# AES register map
Vendor: Texas Instruments
Registers are 32-bit, write-only, no defined reset value unless marked. A register's access mark holds for its fields unless they carry their own. Offsets are as the file gives them; [hi:lo] are bit positions; {n}, {i} and the like mark numbered series; 'fields as' and 'values as' point back to an identical list.

## AES (part 2 of 2) — Register fields should be considered static unless otherwise noted as dynamic.
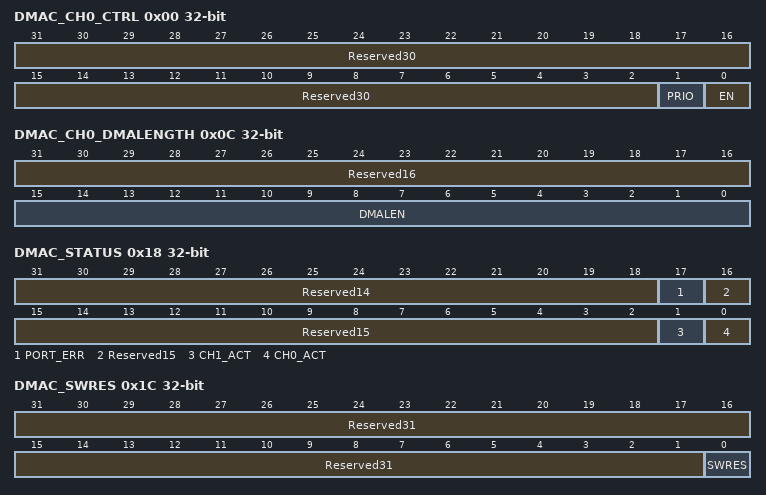
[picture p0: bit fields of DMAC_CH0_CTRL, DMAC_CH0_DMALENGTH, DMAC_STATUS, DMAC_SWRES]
0x00 DMAC_CH0_CTRL rw — Channel control This register is used for channel enabling and priority selection. When a channel is disabled, it becomes inactive only when all ongoing requests are finished.
  [31:2] Reserved30 — Should be written with 0s and ignored on read
  [1] PRIO — Channel priority 0: Low 1: High If both channels have the same priority, access of the channels to the external port is arbitrated using the round robin scheme. If one channel has a high priority and another one low, the channel with the high priority is served first, in case of simultaneous access requests.
  [0] EN — Channel enable 0: Disabled 1: Enable Note: Disabling an active channel interrupts the DMA operation. The ongoing block transfer completes, but no new transfers are requested.
0x04 DMAC_CH0_EXTADDR rw — Channel external address
  [31:0] ADDR — Channel external address value When read during operation, it holds the last updated external address after being sent to the master interface.
0x0C DMAC_CH0_DMALENGTH rw — Channel DMA length
  [31:16] Reserved16 — Should be written with 0s and ignored on read
  [15:0] DMALEN — Channel DMA length in bytes During configuration, this register contains the DMA transfer length in bytes. During operation, it contains the last updated value of the DMA transfer length after being sent to the master interface. Note: Setting this register to a nonzero value starts the transfer if the channel is enabled. Therefore, this register must be written last when setting up a DMA channel.
0x18 DMAC_STATUS ro — DMAC status This register provides the actual state of each DMA channel. It also reports port errors in case these were received by the master interface module during the data transfer.
  [31:18] Reserved14 — Bits should be ignored on read.
  [17] PORT_ERR — Reflects possible transfer errors on the AHB port.
  [16:2] Reserved15 — Bits should be ignored on read.
  [1] CH1_ACT — A value of 1 indicates that channel 1 is active (DMA transfer on-going).
  [0] CH0_ACT — A value of 1 indicates that channel 0 is active (DMA transfer on-going).
0x1C DMAC_SWRES — DMAC software reset register Software reset is used to reset the DMAC to stop all transfers and clears the port error status register. After the software reset is performed, all the channels are disabled and no new requests are performed by the channels. The DMAC waits for the existing (active) requests to finish and accordingly sets the DMAC status registers.
  [31:1] Reserved31 — Bits should be written with a value of 0.
  [0] SWRES — Software reset enable 0 = Disabled 1 = Enabled (self-cleared to 0) Completion of the software reset must be checked through the DMAC_STATUS register.
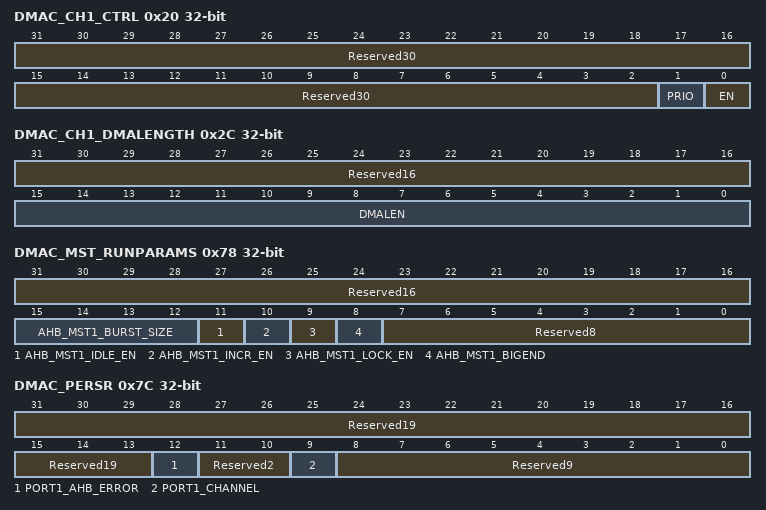
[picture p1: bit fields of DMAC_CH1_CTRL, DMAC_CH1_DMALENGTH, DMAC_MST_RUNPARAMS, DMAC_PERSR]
0x20 DMAC_CH1_CTRL rw — Channel control This register is used for channel enabling and priority selection. When a channel is disabled, it becomes inactive only when all ongoing requests are finished.
  fields as DMAC_CH0_CTRL
0x24 DMAC_CH1_EXTADDR rw — Channel external address
  [31:0] ADDR — Channel external address value. When read during operation, it holds the last updated external address after being sent to the master interface.
0x2C DMAC_CH1_DMALENGTH rw — Channel DMA length
  [31:16] Reserved16 — Should be written with 0s and ignored on read
  [15:0] DMALEN — Channel DMA length in bytes. During configuration, this register contains the DMA transfer length in bytes. During operation, it contains the last updated value of the DMA transfer length after being sent to the master interface. Note: Setting this register to a nonzero value starts the transfer if the channel is enabled. Therefore, this register must be written last when setting up a DMA channel.
0x78 DMAC_MST_RUNPARAMS rw — DMAC master run-time parameters This register defines all the run-time parameters for the AHB master interface port. These parameters are required for the proper functioning of the EIP-101m AHB master adapter.
  [31:16] Reserved16 — Should be written with 0s and ignored on read
  [15:12] AHB_MST1_BURST_SIZE — Maximum burst size that can be performed on the AHB bus 0010b = 4 bytes (default) 0011b = 8 bytes 0100b = 16 bytes 0101b = 32 bytes 0110b = 64 bytes Others = Reserved
  [11] AHB_MST1_IDLE_EN — Idle insertion between consecutive burst transfers on AHB 0: No Idle insertion 1: Idle insertion
  [10] AHB_MST1_INCR_EN — Burst length type of AHB transfer 0: Unspecified length burst transfers 1: Fixed length burst or single transfers
  [9] AHB_MST1_LOCK_EN — Locked transform on AHB 0: Transfers are not locked 1: Transfers are locked
  [8] AHB_MST1_BIGEND — Endianess for the AHB master 0: Little endian 1: Big endian
  [7:0] Reserved8 — Should be written with 0s and ignored on read
0x7C DMAC_PERSR ro — DMAC port error raw status register This register provides the actual status of individual port errors. It also indicates which channel is serviced by an external AHB port (which is frozen by a port error). A port error aborts operations on all serviced channels (channel enable bit is forced to 0) and prevents further transfers via that port until the error is cleared by writing to the DMAC_SWRES register.
  [31:13] Reserved19 — Bits should be ignored on read
  [12] PORT1_AHB_ERROR — A value of 1 indicates that the EIP-101 has detected an AHB bus error
  [11:10] Reserved2 — Bits should be ignored on read
  [9] PORT1_CHANNEL — Indicates which channel has serviced last (channel 0 or channel 1) by AHB master port.
  [8:0] Reserved9 — Bits should be ignored on read
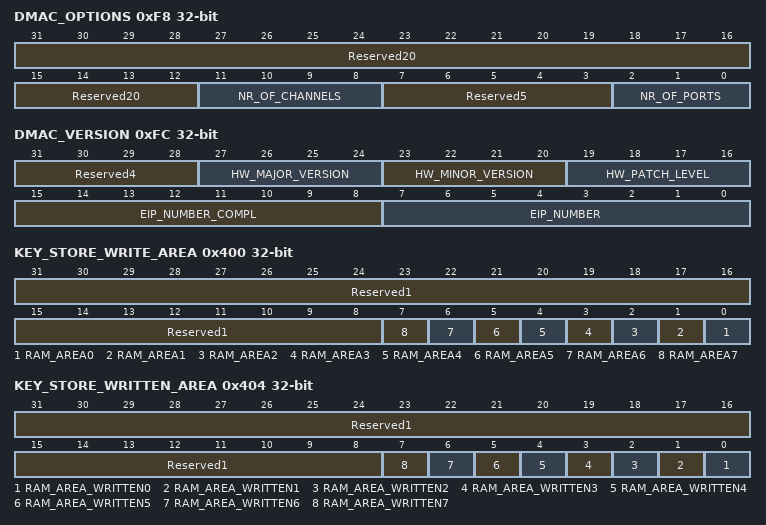
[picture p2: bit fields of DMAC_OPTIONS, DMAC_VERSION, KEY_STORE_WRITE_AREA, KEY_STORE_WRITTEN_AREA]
0xF8 DMAC_OPTIONS ro — DMAC options register These registers contain information regarding the different options configured in this DMAC.
  [31:12] Reserved20 — Bits should be ignored on read
  [11:8] NR_OF_CHANNELS — Number of channels implemented, value in the range 1-8.
  [7:3] Reserved5 — Bits should be ignored on read
  [2:0] NR_OF_PORTS — Number of ports implemented, value in range 1-4.
0xFC DMAC_VERSION ro — DMAC version register This register contains an indication (or signature) of the EIP type of this DMAC, as well as the hardware version/patch numbers.
  [31:28] Reserved4 — Bits should be ignored on read
  [27:24] HW_MAJOR_VERSION — Major version number
  [23:20] HW_MINOR_VERSION — Minor version number
  [19:16] HW_PATCH_LEVEL — Patch level Starts at 0 at first delivery of this version
  [15:8] EIP_NUMBER_COMPL — Bit-by-bit complement of the EIP_NUMBER field bits.
  [7:0] EIP_NUMBER — Binary encoding of the EIP-number of this DMA controller (209)
0x400 KEY_STORE_WRITE_AREA rw — Key store write area register This register defines where the keys should be written in the key store RAM. After writing this register, the key store module is ready to receive the keys through a DMA operation. In case the key data transfer triggered an error in the key store, the error will be available in the interrupt status register after the DMA is finished. The key store write-error is asserted when the programmed/selected area is not completely written. This error is also asserted when the DMA operation writes to ram areas that are not selected. The key store RAM is divided into 8 areas of 128 bits. 192-bit keys written in the key store RAM should start on boundaries of 256 bits. This means that writing a 192-bit key to the key store RAM must be done by writing 256 bits of data with the 64 most-significant bits set to 0. These bits are ignored by the AES engine.
  [31:8] Reserved1 — Write 0s and ignore on reading
  [n] RAM_AREA{n} (n=0..7) — Each RAM_AREAx represents an area of 128 bits. Select the key store RAM area(s) where the key(s) needs to be written 0: RAM_AREA{n} is not selected to be written. 1: RAM_AREA{n} is selected to be written. Writing to multiple RAM locations is possible only when the selected RAM areas are sequential. Keys that require more than one RAM locations (key size is 192 or 256 bits), must start at one of the following areas: RAM_AREA0, RAM_AREA2, RAM_AREA4, or RAM_AREA6.
0x404 KEY_STORE_WRITTEN_AREA rw — Key store written area register This register shows which areas of the key store RAM contain valid written keys. When a new key needs to be written to the key store, on a location that is already occupied by a valid key, this key area must be cleared first. This can be done by writing this register before the new key is written to the key store memory. Attempting to write to a key area that already contains a valid key is not allowed and results in an error.
  [31:8] Reserved1 — Write 0s and ignore on reading
  [n] RAM_AREA_WRITTEN{n} (n=0..7) — Read operation: 0: This RAM area is not written with valid key information. 1: This RAM area is written with valid key information. Each individual ram_area_writtenx bit can be reset by writing 1. Note: This register is reset on a soft reset from the master control module. After a soft reset, all keys must be rewritten to the key store memory.
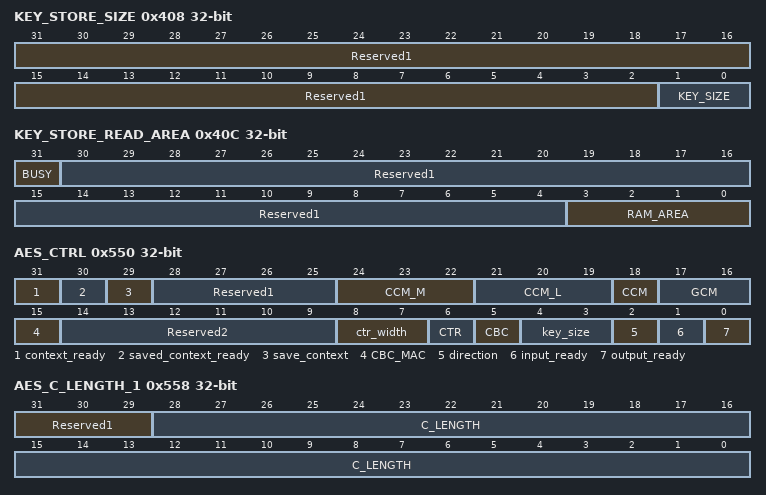
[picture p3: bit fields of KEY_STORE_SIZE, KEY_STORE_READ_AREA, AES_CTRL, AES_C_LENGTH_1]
0x408 KEY_STORE_SIZE rw — Key store size register This register defines the size of the keys that are written with DMA. This register should be configured before writing to the KEY_STORE_WRITE_AREA register.
  [31:2] Reserved1 — Write 0s and ignore on reading
  [1:0] KEY_SIZE — Key size: 00: Reserved 01: 128 bits 10: 192 bits 11: 256 bits When writing this to this register, the KEY_STORE_WRITTEN_AREA register is reset.
0x40C KEY_STORE_READ_AREA access per field — Key store read area register This register selects the key store RAM area from where the key needs to be read that will be used for an AES operation. The operation directly starts after writing this register. When the operation is finished, the status of the key store read operation is available in the interrupt status register. Key store read error is asserted when a RAM area is selected which does not contain valid written key.
  [31] BUSY ro — Key store operation busy status flag (read only): 0: Operation is complete. 1: Operation is not completed and the key store is busy.
  [30:4] Reserved1 rw — Write 0s and ignore on reading
  [3:0] RAM_AREA rw — Selects the area of the key store RAM from where the key needs to be read that will be writen to the AES engine RAM_AREA: 0000: RAM_AREA0 0001: RAM_AREA1 0010: RAM_AREA2 0011: RAM_AREA3 0100: RAM_AREA4 0101: RAM_AREA5 0110: RAM_AREA6 0111: RAM_AREA7 1000: no RAM area selected 1001-1111: Reserved RAM areas RAM_AREA0, RAM_AREA2, RAM_AREA4 and RAM_AREA6 are the only valid read areas for 192 and 256 bits key sizes. Only RAM areas that contain valid written keys can be selected.
{0x500+4i} AES_KEY2_{i} (i=0..3) — AES_KEY2_{i} / AES_GHASH_H_IN_{i} Second Key / GHASH Key (internal, but clearable) The following registers are not accessible through the host for reading and writing. They are used to store internally calculated key information and intermediate results. However, when the host performs a write to the any of the respective AES_KEY2_n or AES_KEY3_n addresses, respectively the whole 128-bit AES_KEY2_n or AES_KEY3_n register is cleared to 0s. The AES_GHASH_H_IN_n registers (required for GHASH, which is part of GCM) are mapped to the AES_KEY2_n registers. The (intermediate) authentication result for GCM and CCM is stored in the AES_KEY3_n register.
  [31:0] AES_KEY2 — AES_KEY2/AES_GHASH_H[{32i+31}:{32i}] For GCM: -[127:0] - GHASH_H - The internally calculated GHASH key is stored in these registers. Only used for modes that use the GHASH function (GCM). -[255:128] - This register is used to store intermediate values and is initialized with 0s when loading a new key. For CCM: -[255:0] - This register is used to store intermediate values. For CBC-MAC: -[255:0] - ZEROES - This register must remain 0.
{0x510+4i} AES_KEY3_{i} (i=0..3) — AES_KEY3_{i} / AES_KEY2_{i+4} Third Key / Second Key (internal, but clearable) The following registers are not accessible through the host for reading and writing. They are used to store internally calculated key information and intermediate results. However, when the host performs a write to the any of the respective AES_KEY2_n or AES_KEY3_n addresses, respectively the whole 128-bit AES_KEY2_n or AES_KEY3_n register is cleared to 0s. The AES_GHASH_H_IN_n registers (required for GHASH, which is part of GCM) are mapped to the AES_KEY2_n registers. The (intermediate) authentication result for GCM and CCM is stored in the AES_KEY3_n register.
  [31:0] AES_KEY3 — AES_KEY3[{32i+31}:{32i}]/AES_KEY2[{32i+159}:{32i+128}] For GCM: -[127:0] - GHASH_H - The internally calculated GHASH key is stored in these registers. Only used for modes that use the GHASH function (GCM). -[255:128] - This register is used to store intermediate values and is initialized with 0s when loading a new key. For CCM: -[255:0] - This register is used to store intermediate values. For CBC-MAC: -[255:0] - ZEROES - This register must remain 0.
{0x540+4i} AES_IV_{i} rw (i=0..3) — AES initialization vector registers These registers are used to provide and read the IV from the AES engine.
  [31:0] AES_IV — AES_IV[{32i+31}:{32i}] Initialization vector Used for regular non-ECB modes (CBC/CTR): -[127:0] - AES_IV - For regular AES operations (CBC and CTR) these registers must be written with a new 128-bit IV. After an operation, these registers contain the latest 128-bit result IV, generated by the EIP-120t. If CTR mode is selected, this value is incremented with 0x1: After first use - When a new data block is submitted to the engine For GCM: -[127:0] - AES_IV - For GCM operations, these registers must be written with a new 128-bit IV. After an operation, these registers contain the updated 128-bit result IV, generated by the EIP-120t. Note that bits [127:96] of the IV represent the initial counter value (which is 1 for GCM) and must therefore be initialized to 0x01000000. This value is incremented with 0x1: After first use - When a new data block is submitted to the engine. For CCM: -[127:0] - A0: For CCM this field must be written with value A0, this value is the concatenation of: A0-flags (5-bits of 0 and 3-bits 'L'), Nonce and counter value. 'L' must be a copy from the 'L' value of the AES_CTRL register. This 'L' indicates the width of the Nonce and counter. The loaded counter must be initialized to 0. The total width of A0 is 128-bit. For CBC-MAC: -[127:0] - Zeroes - For CBC-MAC this register must be written with 0s at the start of each operation. After an operation, these registers contain the 128-bit TAG output, generated by the EIP-120t.
0x550 AES_CTRL access per field — AES input/output buffer control and mode register This register specifies the AES mode of operation for the EIP-120t. Electronic codebook (ECB) mode is automatically selected if bits [28:5] of this register are all 0.
  [31] context_ready ro — If 1, this read-only status bit indicates that the context data registers can be overwritten and the host is permitted to write the next context.
  [30] saved_context_ready rw — If 1, this status bit indicates that an AES authentication TAG and/or IV block(s) is/are available for the host to retrieve. This bit is only asserted if the save_context bit is set to 1. The bit is mutual exclusive with the context_ready bit. Writing one clears the bit to 0, indicating the AES core can start its next operation. This bit is also cleared when the 4th word of the output TAG and/or IV is read. Note: All other mode bit writes are ignored when this mode bit is written with 1. Note: This bit is controlled automatically by the EIP-120t for TAG read DMA operations.
  [29] save_context rw — This bit indicates that an authentication TAG or result IV needs to be stored as a result context. Typically this bit must be set for authentication modes returning a TAG (CBC-MAC, GCM and CCM), or for basic encryption modes that require future continuation with the current result IV. If this bit is set, the engine retains its full context until the TAG and/or IV registers are read. The TAG or IV must be read before the AES engine can start a new operation.
  [28:25] Reserved1 rw — Bits should be written with a value of 0. and ignored on a read.
  [24:22] CCM_M rw — Defines M, which indicates the length of the authentication field for CCM operations; the authentication field length equals two times (the value of CCM-M plus one). Note: The EIP-120t always returns a 128-bit authentication field, of which the M least significant bytes are valid. All values are supported.
  [21:19] CCM_L rw — Defines L, which indicates the width of the length field for CCM operations; the length field in bytes equals the value of CMM-L plus one. All values are supported.
  [18] CCM rw — If set to 1, AES-CCM is selected AES-CCM is a combined mode, using AES for authentication and encryption. Note: Selecting AES-CCM mode requires writing of the AAD length register after all other registers. Note: The CTR mode bit in this register must also be set to 1 to enable AES-CTR; selecting other AES modes than CTR mode is invalid.
  [17:16] GCM rw — Set these bits to 11 to select AES-GCM mode. AES-GCM is a combined mode, using the Galois field multiplier GF(2 to the power of 128) for authentication and AES-CTR mode for encryption. Note: The CTR mode bit in this register must also be set to 1 to enable AES-CTR Bit combination description: 00 = No GCM mode 01 = Reserved, do not select 10 = Reserved, do not select 11 = Autonomous GHASH (both H- and Y0-encrypted calculated internally) Note: The EIP-120t-1 configuration only supports mode 11 (autonomous GHASH), other GCM modes are not allowed.
  [15] CBC_MAC rw — Set to 1 to select AES-CBC MAC mode. The direction bit must be set to 1 for this mode. Selecting this mode requires writing the length register after all other registers.
  [14:9] Reserved2 rw — Bits should be written with a value of 0. and ignored on a read.
  [8:7] ctr_width rw — Specifies the counter width for AES-CTR mode 00 = 32-bit counter 01 = 64-bit counter 10 = 96-bit counter 11 = 128-bit counter
  [6] CTR rw — If set to 1, AES counter mode (CTR) is selected. Note: This bit must also be set for GCM and CCM, when encryption/decryption is required.
  [5] CBC rw — If set to 1, cipher-block-chaining (CBC) mode is selected.
  [4:3] key_size ro — This read-only field specifies the key size. The key size is automatically configured when a new key is loaded through the key store module. 00 = N/A - Reserved 01 = 128-bit 10 = 192-bit 11 = 256-bit
  [2] direction rw — If set to 1 an encrypt operation is performed. If set to 0 a decrypt operation is performed. This bit must be written with a 1 when CBC-MAC is selected.
  [1] input_ready rw — If 1, this status bit indicates that the 16-byte AES input buffer is empty. The host is permitted to write the next block of data. Writing 0 clears the bit to 0 and indicates that the AES core can use the provided input data block. Writing 1 to this bit is ignored. Note: For DMA operations, this bit is automatically controlled by the EIP-120t. After reset, this bit is 0. After writing a context, this bit becomes 1.
  [0] output_ready rw — If 1, this status bit indicates that an AES output block is available to be retrieved by the host. Writing 0 clears the bit to 0 and indicates that output data is read by the host. The AES core can provide a next output data block. Writing 1 to this bit is ignored. Note: For DMA operations, this bit is automatically controlled by the EIP-120t.
0x554 AES_C_LENGTH_0 — AES crypto length registers (LSW) These registers are used to write the Length values to the EIP-120t. While processing, the length values decrement to 0. If both lengths are 0, the data stream is finished and a new context is requested. For basic AES modes (ECB, CBC, and CTR), a crypto length of 0 can be written if multiple streams need to be processed with the same key. Writing 0 length results in continued data requests until a new context is written. For the other modes (CBC-MAC, GCM, and CCM) no (new) data requests are done if the length decrements to or equals 0. It is advised to write a new length per packet. If the length registers decrement to 0, no new data is processed until a new context or length value is written. When writing a new mode without writing the length registers, the length register values from the previous context is reused.
  [31:0] C_LENGTH — C_LENGTH[31:0] Bits [60:0] of the crypto length registers (LSW and MSW) store the cryptographic data length in bytes for all modes. Once processing with this context is started, this length decrements to 0. Data lengths up to (261: 1) bytes are allowed. For GCM, any value up to 236 - 32 bytes can be used. This is because a 32-bit counter mode is used; the maximum number of 128-bit blocks is 232 - 2, resulting in a maximum number of bytes of 236 - 32. A write to this register triggers the engine to start using this context. This is valid for all modes except GCM and CCM. Note: For the combined modes (GCM and CCM), this length does not include the authentication only data; the authentication length is specified in the AES_AUTH_LENGTH register below. All modes must have a length greater than 0. For the combined modes, it is allowed to have one of the lengths equal to 0. For the basic encryption modes (ECB, CBC, and CTR) it is allowed to program zero to the length field; in that case the length is assumed infinite. All data must be byte (8-bit) aligned for stream cipher modes; bit aligned data streams are not supported by the EIP-120t. For block cipher modes, the data length must be programmed in multiples of the block cipher size, 16 bytes. For a host read operation, these registers return all-0s.
0x558 AES_C_LENGTH_1 — AES crypto length registers (MSW) These registers are used to write the Length values to the EIP-120t. While processing, the length values decrement to 0. If both lengths are 0, the data stream is finished and a new context is requested. For basic AES modes (ECB, CBC, and CTR), a crypto length of 0 can be written if multiple streams need to be processed with the same key. Writing 0 length results in continued data requests until a new context is written. For the other modes (CBC-MAC, GCM and CCM) no (new) data requests are done if the length decrements to or equals 0. It is advised to write a new length per packet. If the length registers decrement to 0, no new data is processed until a new context or length value is written. When writing a new mode without writing the length registers, the length register values from the previous context is reused.
  [31:29] Reserved1 — Bits should be written with a value of 0. and ignored on a read.
  [28:0] C_LENGTH — C_LENGTH[60:32] Bits [60:0] of the crypto length registers (LSW and MSW) store the cryptographic data length in bytes for all modes. Once processing with this context is started, this length decrements to 0. Data lengths up to (261: 1) bytes are allowed. For GCM, any value up to 236 - 32 bytes can be used. This is because a 32-bit counter mode is used; the maximum number of 128-bit blocks is 232 - 2, resulting in a maximum number of bytes of 236 - 32. A write to this register triggers the engine to start using this context. This is valid for all modes except GCM and CCM. Note: For the combined modes (GCM and CCM), this length does not include the authentication only data; the authentication length is specified in the AES_AUTH_LENGTH register below. All modes must have a length greater than 0. For the combined modes, it is allowed to have one of the lengths equal to 0. For the basic encryption modes (ECB, CBC, and CTR) it is allowed to program zero to the length field; in that case the length is assumed infinite. All data must be byte (8-bit) aligned for stream cipher modes; bit aligned data streams are not supported by the EIP-120t. For block cipher modes, the data length must be programmed in multiples of the block cipher size, 16 bytes. For a host read operation, these registers return all-0s.
0x55C AES_AUTH_LENGTH — Authentication length register
  [31:0] AUTH_LENGTH — Bits [31:0] of the authentication length register store the authentication data length in bytes for combined modes only (GCM or CCM). Supported AAD-lengths for CCM are from 0 to (2^16 - 2^8) bytes. For GCM any value up to (2^32 - 1) bytes can be used. Once processing with this context is started, this length decrements to 0. A write to this register triggers the engine to start using this context for GCM and CCM. For a host read operation, these registers return all-0s.
0x560 AES_DATA_IN_OUT_0 — Data input/output registers The data registers are typically accessed through the DMA and not with host writes and/or reads. However, for debugging purposes the data input/output registers can be accessed via host write and read operations. The registers are used to buffer the input/output data blocks to/from the EIP-120t. Note: The data input buffer (AES_DATA_IN_n) and data output buffer (AES_DATA_OUT_n) are mapped to the same address locations. Writes (both DMA and host) to these addresses load the Input Buffer while reads pull from the Output Buffer. Therefore, for write access, the data input buffer is written; for read access, the data output buffer is read. The data input buffer must be written before starting an operation. The data output buffer contains valid data on completion of an operation. Therefore, any 128-bit data block can be split over multiple 32-bit word transfers; these can be mixed with other host transfers over the external interface.
  [31:0] AES_DATA_IN_OUT — AES input data[31:0] / AES output data[31:0] Data registers for input/output block data to/from the EIP-120t. For normal operations, this register is not used, since data input and output is transferred from and to the AES core via DMA. For a host write operation, these registers must be written with the 128-bit input block for the next AES operation. Writing at a word-aligned offset within this address range stores the word (4 bytes) of data into the corresponding position of 4-word deep (16 bytes = 128-bit AES block) data input buffer. This buffer is used for the next AES operation. If the last data block is not completely filled with valid data (see notes below), it is allowed to write only the words with valid data. Next AES operation is triggered by writing to the input_ready flag of the AES_CTRL register. For a host read operation, these registers contain the 128-bit output block from the latest AES operation. Reading from a word-aligned offset within this address range reads one word (4 bytes) of data out the 4-word deep (16 bytes = 128-bits AES block) data output buffer. The words (4 words, one full block) should be read before the core will move the next block to the data output buffer. To empty the data output buffer, the output_ready flag of the AES_CTRL register must be written. For the modes with authentication (CBC-MAC, GCM and CCM), the invalid (message) bytes/words can be written with any data. Note: AES typically operates on 128 bits block multiple input data. The CTR, GCM and CCM modes form an exception. The last block of a CTR-mode message may contain less than 128 bits (refer to [NIST 800-38A]). For GCM/CCM, the last block of both AAD and message data may contain less than 128 bits (refer to [NIST 800-38D]). The EIP-120t automatically pads or masks misaligned ending data blocks with 0s for GCM, CCM and CBC-MAC. For CTR mode, the remaining data in an unaligned data block is ignored. Note: The AAD / authentication only data is not copied to the output buffer but only used for authentication.
{0x560+4i} AES_DATA_IN_OUT_{i} (i=1..3) — Data Input/Output Registers The data registers are typically accessed via DMA and not with host writes and/or reads. However, for debugging purposes the Data Input/Output Registers can be accessed via host write and read operations. The registers are used to buffer the input/output data blocks to/from the EIP-120t. Note: The data input buffer (AES_DATA_IN_n) and data output buffer (AES_DATA_OUT_n) are mapped to the same address locations. Writes (both DMA and host) to these addresses load the Input Buffer while reads pull from the Output Buffer. Therefore, for write access, the data input buffer is written; for read access, the data output buffer is read. The data input buffer must be written before starting an operation. The data output buffer contains valid data on completion of an operation. Therefore, any 128-bit data block can be split over multiple 32-bit word transfers; these can be mixed with other host transfers over the external interface.
  [31:0] AES_DATA_IN_OUT — AES input data[{32i+31}:{32i}] / AES output data[{32i+31}:{32i}] Data registers for input/output block data to/from the EIP-120t. For normal operations, this register is not used, since data input and output is transferred from and to the AES core via DMA. For a host write operation, these registers must be written with the 128-bit input block for the next AES operation. Writing at a word-aligned offset within this address range stores the word (4 bytes) of data into the corresponding position of 4-word deep (16 bytes = 128-bit AES block) data input buffer. This buffer is used for the next AES operation. If the last data block is not completely filled with valid data (see notes below), it is allowed to write only the words with valid data. Next AES operation is triggered by writing to the input_ready flag of the AES_CTRL register. For a host read operation, these registers contain the 128-bit output block from the latest AES operation. Reading from a word-aligned offset within this address range reads one word (4 bytes) of data out the 4-word deep (16 bytes = 128-bits AES block) data output buffer. The words (4 words, one full block) should be read before the core will move the next block to the data output buffer. To empty the data output buffer, the output_ready flag of the AES_CTRL register must be written. For the modes with authentication (CBC-MAC, GCM and CCM), the invalid (message) bytes/words can be written with any data. Note: AES typically operates on 128 bits block multiple input data. The CTR, GCM and CCM modes form an exception. The last block of a CTR-mode message may contain less than 128 bits (refer to [NIST 800-38A]). For GCM/CCM, the last block of both AAD and message data may contain less than 128 bits (refer to [NIST 800-38D]). The EIP-120t automatically pads or masks misaligned ending data blocks with 0s for GCM, CCM and CBC-MAC. For CTR mode, the remaining data in an unaligned data block is ignored. Note: The AAD / authentication only data is not copied to the output buffer but only used for authentication.
